AUTOSAR XML (schema 4-0-3)
package /ComponentTypes
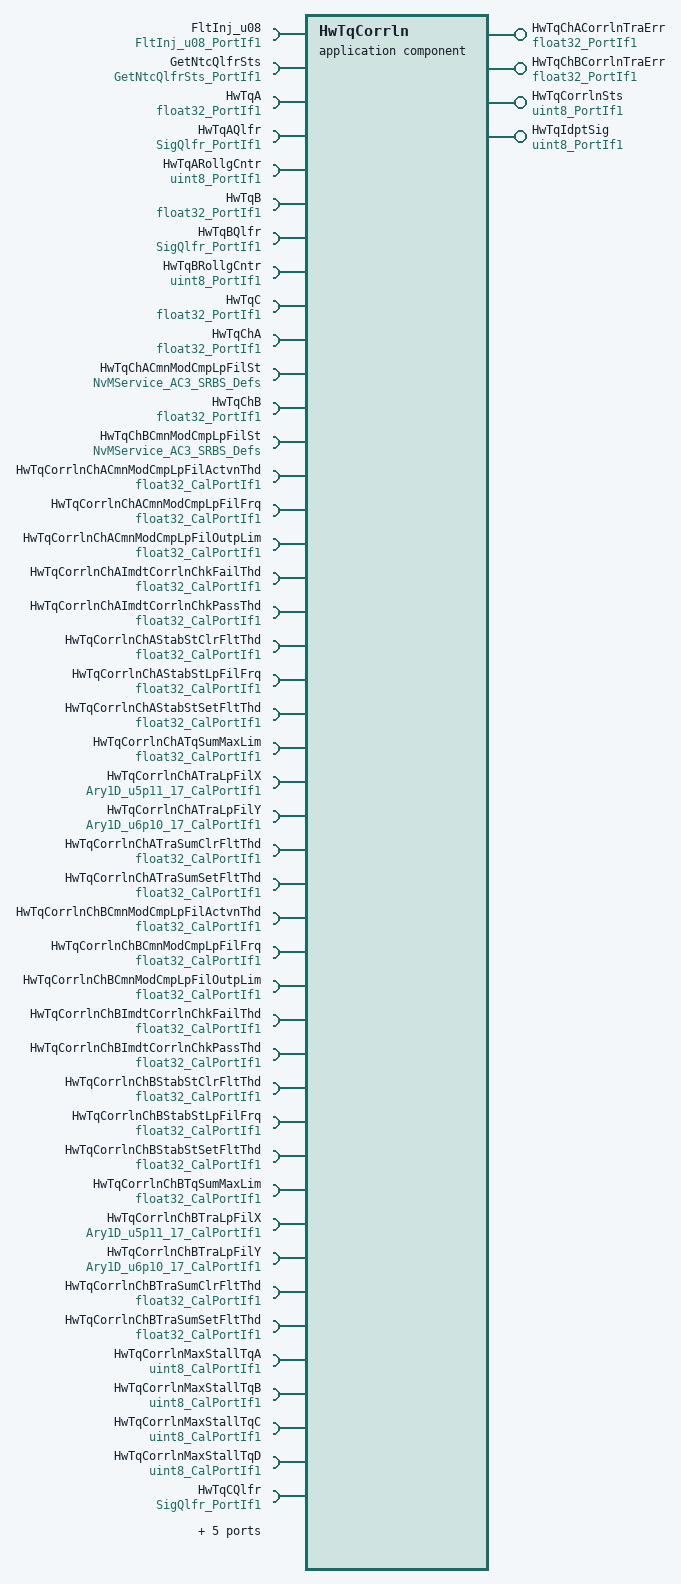
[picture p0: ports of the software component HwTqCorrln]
  application sw component type HwTqCorrln
    4 x provide port:
      HwTqChACorrlnTraErr: nonqueued-sender-com-spec{data-element=Val, init-value=0}, provided-interface=float32_PortIf1
      HwTqChBCorrlnTraErr: nonqueued-sender-com-spec{data-element=Val, init-value=0}, provided-interface=float32_PortIf1
      HwTqCorrlnSts: nonqueued-sender-com-spec{data-element=Val, init-value=15}, provided-interface=uint8_PortIf1
      HwTqIdptSig: nonqueued-sender-com-spec{data-element=Val, init-value=4}, provided-interface=uint8_PortIf1
    49 x require port:
      FltInj_u08: required-interface=FltInj_u08_PortIf1
      GetNtcQlfrSts: required-interface=GetNtcQlfrSts_PortIf1
      HwTqA: nonqueued-receiver-com-spec{data-element=Val, filter=data-filter-type=ALWAYS, init-value=0}, required-interface=float32_PortIf1
      HwTqAQlfr: nonqueued-receiver-com-spec{data-element=Val, filter=data-filter-type=ALWAYS, init-value=0}, required-interface=SigQlfr_PortIf1
      HwTqARollgCntr: nonqueued-receiver-com-spec{data-element=Val, filter=data-filter-type=ALWAYS, init-value=0}, required-interface=uint8_PortIf1
      HwTqB: nonqueued-receiver-com-spec{data-element=Val, filter=data-filter-type=ALWAYS, init-value=0}, required-interface=float32_PortIf1
      HwTqBQlfr: nonqueued-receiver-com-spec{data-element=Val, filter=data-filter-type=ALWAYS, init-value=0}, required-interface=SigQlfr_PortIf1
      HwTqBRollgCntr: nonqueued-receiver-com-spec{data-element=Val, filter=data-filter-type=ALWAYS, init-value=0}, required-interface=uint8_PortIf1
      HwTqC: nonqueued-receiver-com-spec{data-element=Val, filter=data-filter-type=ALWAYS, init-value=0}, required-interface=float32_PortIf1
      HwTqChA: nonqueued-receiver-com-spec{data-element=Val, filter=data-filter-type=ALWAYS, init-value=0}, required-interface=float32_PortIf1
      HwTqChACmnModCmpLpFilSt: required-interface=NvMService_AC3_SRBS_Defs
      HwTqChB: nonqueued-receiver-com-spec{data-element=Val, filter=data-filter-type=ALWAYS, init-value=0}, required-interface=float32_PortIf1
      HwTqChBCmnModCmpLpFilSt: required-interface=NvMService_AC3_SRBS_Defs
      HwTqCorrlnChACmnModCmpLpFilActvnThd: parameter-require-com-spec{init-value=0.2857143, parameter=Val}, required-interface=float32_CalPortIf1
      HwTqCorrlnChACmnModCmpLpFilFrq: parameter-require-com-spec{init-value=0.01989437, parameter=Val}, required-interface=float32_CalPortIf1
      HwTqCorrlnChACmnModCmpLpFilOutpLim: parameter-require-com-spec{init-value=0.5714, parameter=Val}, required-interface=float32_CalPortIf1
      HwTqCorrlnChAImdtCorrlnChkFailThd: parameter-require-com-spec{init-value=2.85, parameter=Val}, required-interface=float32_CalPortIf1
      HwTqCorrlnChAImdtCorrlnChkPassThd: parameter-require-com-spec{init-value=2, parameter=Val}, required-interface=float32_CalPortIf1
      HwTqCorrlnChAStabStClrFltThd: parameter-require-com-spec{init-value=2.515, parameter=Val}, required-interface=float32_CalPortIf1
      HwTqCorrlnChAStabStLpFilFrq: parameter-require-com-spec{init-value=0.01989437, parameter=Val}, required-interface=float32_CalPortIf1
      HwTqCorrlnChAStabStSetFltThd: parameter-require-com-spec{init-value=2.85, parameter=Val}, required-interface=float32_CalPortIf1
      HwTqCorrlnChATqSumMaxLim: parameter-require-com-spec{init-value=20, parameter=Val}, required-interface=float32_CalPortIf1
      HwTqCorrlnChATraLpFilX: parameter-require-com-spec{init-value=[0, 1783, 3560, 5342, 7125, 8902, 10685, 12467, 14245, 16027, 17810, 19587, 21370, 23152, 24935, 26712, 28495], parameter=Ary1D}, required-interface=Ary1D_u5p11_17_CalPortIf1
      HwTqCorrlnChATraLpFilY: parameter-require-com-spec{init-value=[34873, 34873, 34873, 34873, 19910, 12411, 9199, 7350, 6137, 5272, 4623, 4119, 3714, 3382, 3104, 2870, 2668], parameter=Ary1D}, required-interface=Ary1D_u6p10_17_CalPortIf1
      HwTqCorrlnChATraSumClrFltThd: parameter-require-com-spec{init-value=1.425, parameter=Val}, required-interface=float32_CalPortIf1
      HwTqCorrlnChATraSumSetFltThd: parameter-require-com-spec{init-value=2.85, parameter=Val}, required-interface=float32_CalPortIf1
      HwTqCorrlnChBCmnModCmpLpFilActvnThd: parameter-require-com-spec{init-value=0.2857143, parameter=Val}, required-interface=float32_CalPortIf1
      HwTqCorrlnChBCmnModCmpLpFilFrq: parameter-require-com-spec{init-value=0.01989437, parameter=Val}, required-interface=float32_CalPortIf1
      HwTqCorrlnChBCmnModCmpLpFilOutpLim: parameter-require-com-spec{init-value=0.5714, parameter=Val}, required-interface=float32_CalPortIf1
      HwTqCorrlnChBImdtCorrlnChkFailThd: parameter-require-com-spec{init-value=2.85, parameter=Val}, required-interface=float32_CalPortIf1
      HwTqCorrlnChBImdtCorrlnChkPassThd: parameter-require-com-spec{init-value=2, parameter=Val}, required-interface=float32_CalPortIf1
      HwTqCorrlnChBStabStClrFltThd: parameter-require-com-spec{init-value=2.515, parameter=Val}, required-interface=float32_CalPortIf1
      HwTqCorrlnChBStabStLpFilFrq: parameter-require-com-spec{init-value=0.01989437, parameter=Val}, required-interface=float32_CalPortIf1
      HwTqCorrlnChBStabStSetFltThd: parameter-require-com-spec{init-value=2.85, parameter=Val}, required-interface=float32_CalPortIf1
      HwTqCorrlnChBTqSumMaxLim: parameter-require-com-spec{init-value=20, parameter=Val}, required-interface=float32_CalPortIf1
      HwTqCorrlnChBTraLpFilX: parameter-require-com-spec{init-value=[0, 1783, 3560, 5342, 7125, 8902, 10685, 12467, 14245, 16027, 17810, 19587, 21370, 23152, 24935, 26712, 28495], parameter=Ary1D}, required-interface=Ary1D_u5p11_17_CalPortIf1
      HwTqCorrlnChBTraLpFilY: parameter-require-com-spec{init-value=[34873, 34873, 34873, 34873, 19910, 12411, 9199, 7350, 6137, 5272, 4623, 4119, 3714, 3382, 3104, 2870, 2668], parameter=Ary1D}, required-interface=Ary1D_u6p10_17_CalPortIf1
      HwTqCorrlnChBTraSumClrFltThd: parameter-require-com-spec{init-value=1.425, parameter=Val}, required-interface=float32_CalPortIf1
      HwTqCorrlnChBTraSumSetFltThd: parameter-require-com-spec{init-value=2.85, parameter=Val}, required-interface=float32_CalPortIf1
      HwTqCorrlnMaxStallTqA: parameter-require-com-spec{init-value=10, parameter=Val}, required-interface=uint8_CalPortIf1
      HwTqCorrlnMaxStallTqB: parameter-require-com-spec{init-value=10, parameter=Val}, required-interface=uint8_CalPortIf1
      HwTqCorrlnMaxStallTqC: parameter-require-com-spec{init-value=10, parameter=Val}, required-interface=uint8_CalPortIf1
      HwTqCorrlnMaxStallTqD: parameter-require-com-spec{init-value=10, parameter=Val}, required-interface=uint8_CalPortIf1
      HwTqCQlfr: nonqueued-receiver-com-spec{data-element=Val, filter=data-filter-type=ALWAYS, init-value=0}, required-interface=SigQlfr_PortIf1
      HwTqCRollgCntr: nonqueued-receiver-com-spec{data-element=Val, filter=data-filter-type=ALWAYS, init-value=0}, required-interface=uint8_PortIf1
      HwTqD: nonqueued-receiver-com-spec{data-element=Val, filter=data-filter-type=ALWAYS, init-value=0}, required-interface=float32_PortIf1
      HwTqDQlfr: nonqueued-receiver-com-spec{data-element=Val, filter=data-filter-type=ALWAYS, init-value=0}, required-interface=SigQlfr_PortIf1
      HwTqDRollgCntr: nonqueued-receiver-com-spec{data-element=Val, filter=data-filter-type=ALWAYS, init-value=0}, required-interface=uint8_PortIf1
      SetNtcSts: required-interface=SetNtcSts_PortIf1
    behavior HwTqCorrln_InternalBehavior
      ar-typed-per-instance-memorys:
        18 x data, all with sw-calibration-access=READ-ONLY:
          HwTqARollgCntrPrev: type=uint8
          HwTqAStallCntrPrev: type=uint8
          HwTqBRollgCntrPrev: type=uint8
          HwTqBStallCntrPrev: type=uint8
          HwTqChACmnModCmpLpFil: type=FilLpRec1
          HwTqChACmnModCmpLpFilSt: type=float32
          HwTqChAImdtCorrlnChk: type=boolean
          HwTqChAStabStLpFil: type=FilLpRec1
          HwTqChATraLpFil: type=FilLpRec1
          HwTqChBCmnModCmpLpFil: type=FilLpRec1
          HwTqChBCmnModCmpLpFilSt: type=float32
          HwTqChBImdtCorrlnChk: type=boolean
          HwTqChBStabStLpFil: type=FilLpRec1
          HwTqChBTraLpFil: type=FilLpRec1
          HwTqCRollgCntrPrev: type=uint8
          HwTqCStallCntrPrev: type=uint8
          HwTqDRollgCntrPrev: type=uint8
          HwTqDStallCntrPrev: type=uint8
      4 x timing event:
        HwTqCorrln_InitEvent: start-on-event=HwTqCorrlnInit1, period=0
        TMT_HwTqCorrlnPer1: start-on-event=HwTqCorrlnPer1, period=0.002
        TMT_HwTqCorrlnPer2: start-on-event=HwTqCorrlnPer2, period=0.004
        TMT_HwTqCorrlnPer3: start-on-event=HwTqCorrlnPer3, period=0.1
      explicit-inter-runnable-variables:
        4 x data:
          HwTqChAAvl: type=boolean, init-value=1
          HwTqChATqSumLim: type=float32, init-value=0
          HwTqChBAvl: type=boolean, init-value=1
          HwTqChBTqSumLim: type=float32, init-value=0
      4 x runnable:
        HwTqCorrlnInit1
        HwTqCorrlnPer1
          data-receive-point-by-arguments:
            12 x access:
              REC_HwTqA_Val: accessed-variable=HwTqA.Val
              REC_HwTqAQlfr_Val: accessed-variable=HwTqAQlfr.Val
              REC_HwTqARollgCntr_Val: accessed-variable=HwTqARollgCntr.Val
              REC_HwTqB_Val: accessed-variable=HwTqB.Val
              REC_HwTqBQlfr_Val: accessed-variable=HwTqBQlfr.Val
              REC_HwTqBRollgCntr_Val: accessed-variable=HwTqBRollgCntr.Val
              REC_HwTqC_Val: accessed-variable=HwTqC.Val
              REC_HwTqCQlfr_Val: accessed-variable=HwTqCQlfr.Val
              REC_HwTqCRollgCntr_Val: accessed-variable=HwTqCRollgCntr.Val
              REC_HwTqD_Val: accessed-variable=HwTqD.Val
              REC_HwTqDQlfr_Val: accessed-variable=HwTqDQlfr.Val
              REC_HwTqDRollgCntr_Val: accessed-variable=HwTqDRollgCntr.Val
          data-send-points:
            access SEND_HwTqCorrlnSts_Val: accessed-variable=HwTqCorrlnSts.Val
          sync call SC_GetNtcQlfrSts_Oper: operation=GetNtcQlfrSts.Oper, timeout=0
          written-local-variables:
            access WRITE_HwTqChAAvl: accessed-variable=HwTqChAAvl
            access WRITE_HwTqChBAvl: accessed-variable=HwTqChBAvl
        HwTqCorrlnPer2
          data-receive-point-by-arguments:
            4 x access:
              REC_HwTqA_Val: accessed-variable=HwTqA.Val
              REC_HwTqB_Val: accessed-variable=HwTqB.Val
              REC_HwTqC_Val: accessed-variable=HwTqC.Val
              REC_HwTqD_Val: accessed-variable=HwTqD.Val
          data-send-points:
            access SEND_HwTqChACorrlnTraErr_Val: accessed-variable=HwTqChACorrlnTraErr.Val
            access SEND_HwTqChBCorrlnTraErr_Val: accessed-variable=HwTqChBCorrlnTraErr.Val
            access SEND_HwTqIdptSig_Val: accessed-variable=HwTqIdptSig.Val
          read-local-variables:
            access READ_HwTqChAAvl: accessed-variable=HwTqChAAvl
            access READ_HwTqChBAvl: accessed-variable=HwTqChBAvl
          sync call SC_FltInj_u08_Oper: operation=FltInj_u08.Oper, timeout=0
          sync call SC_GetNtcQlfrSts_Oper: operation=GetNtcQlfrSts.Oper, timeout=0
          sync call SC_SetNtcSts_Oper: operation=SetNtcSts.Oper, timeout=0
          written-local-variables:
            access WRITE_HwTqChATqSumLim: accessed-variable=HwTqChATqSumLim
            access WRITE_HwTqChBTqSumLim: accessed-variable=HwTqChBTqSumLim
        HwTqCorrlnPer3
          data-receive-point-by-arguments:
            access REC_HwTqChA_Val: accessed-variable=HwTqChA.Val
            access REC_HwTqChB_Val: accessed-variable=HwTqChB.Val
          read-local-variables:
            access READ_HwTqChATqSumLim: accessed-variable=HwTqChATqSumLim
            access READ_HwTqChBTqSumLim: accessed-variable=HwTqChBTqSumLim
          sync call SC_HwTqChACmnModCmpLpFilSt_SetRamBlockStatus: operation=HwTqChACmnModCmpLpFilSt.SetRamBlockStatus, timeout=0
          sync call SC_HwTqChBCmnModCmpLpFilSt_SetRamBlockStatus: operation=HwTqChBCmnModCmpLpFilSt.SetRamBlockStatus, timeout=0
      swc service dependency NvmHwTqChACmnModCmpLpFilSt
        assigned-datas:
          role=ramBlock, used-data-element=HwTqChACmnModCmpLpFilSt
          role=defaultValue, used-parameter-element=HwTqChACmnModCmpLpFilStDft
        assigned-ports:
          port-prototype=HwTqChACmnModCmpLpFilSt, role=NvMService_AC3_SRBS_Defs
          port-prototype=HwTqChACmnModCmpLpFilSt, role=NvMService_AC3_SRBS_Defs
        service-needs:
          nv block needs NvmHwTqChACmnModCmpLpFilSt: n-data-sets=0, readonly=false, reliability=ERROR-DETECTION, resistant-to-changed-sw=true, restore-at-start=true, store-at-shutdown=true, write-only-once=false, writing-frequency=0, writing-priority=LOW
      swc service dependency NvmHwTqChBCmnModCmpLpFilSt
        assigned-datas:
          role=ramBlock, used-data-element=HwTqChBCmnModCmpLpFilSt
          role=defaultValue, used-parameter-element=HwTqChBCmnModCmpLpFilStDft
        assigned-ports:
          port-prototype=HwTqChBCmnModCmpLpFilSt, role=NvMService_AC3_SRBS_Defs
          port-prototype=HwTqChBCmnModCmpLpFilSt, role=NvMService_AC3_SRBS_Defs
        service-needs:
          nv block needs NvmHwTqChBCmnModCmpLpFilSt: n-data-sets=0, readonly=false, reliability=ERROR-DETECTION, resistant-to-changed-sw=true, restore-at-start=true, store-at-shutdown=true, write-only-once=false, writing-frequency=0, writing-priority=LOW
      shared-parameters:
        parameter data prototype HwTqChACmnModCmpLpFilStDft: sw-calibration-access=READ-WRITE, type=float32, init-value=0
        parameter data prototype HwTqChBCmnModCmpLpFilStDft: sw-calibration-access=READ-WRITE, type=float32, init-value=0
  swc implementation HwTqCorrln_Implementation: behavior=HwTqCorrln_InternalBehavior
    code-descriptors:
      code Default: artifact-descriptors=autosar-engineering-object={short-label=Default, category=SWSRC}
